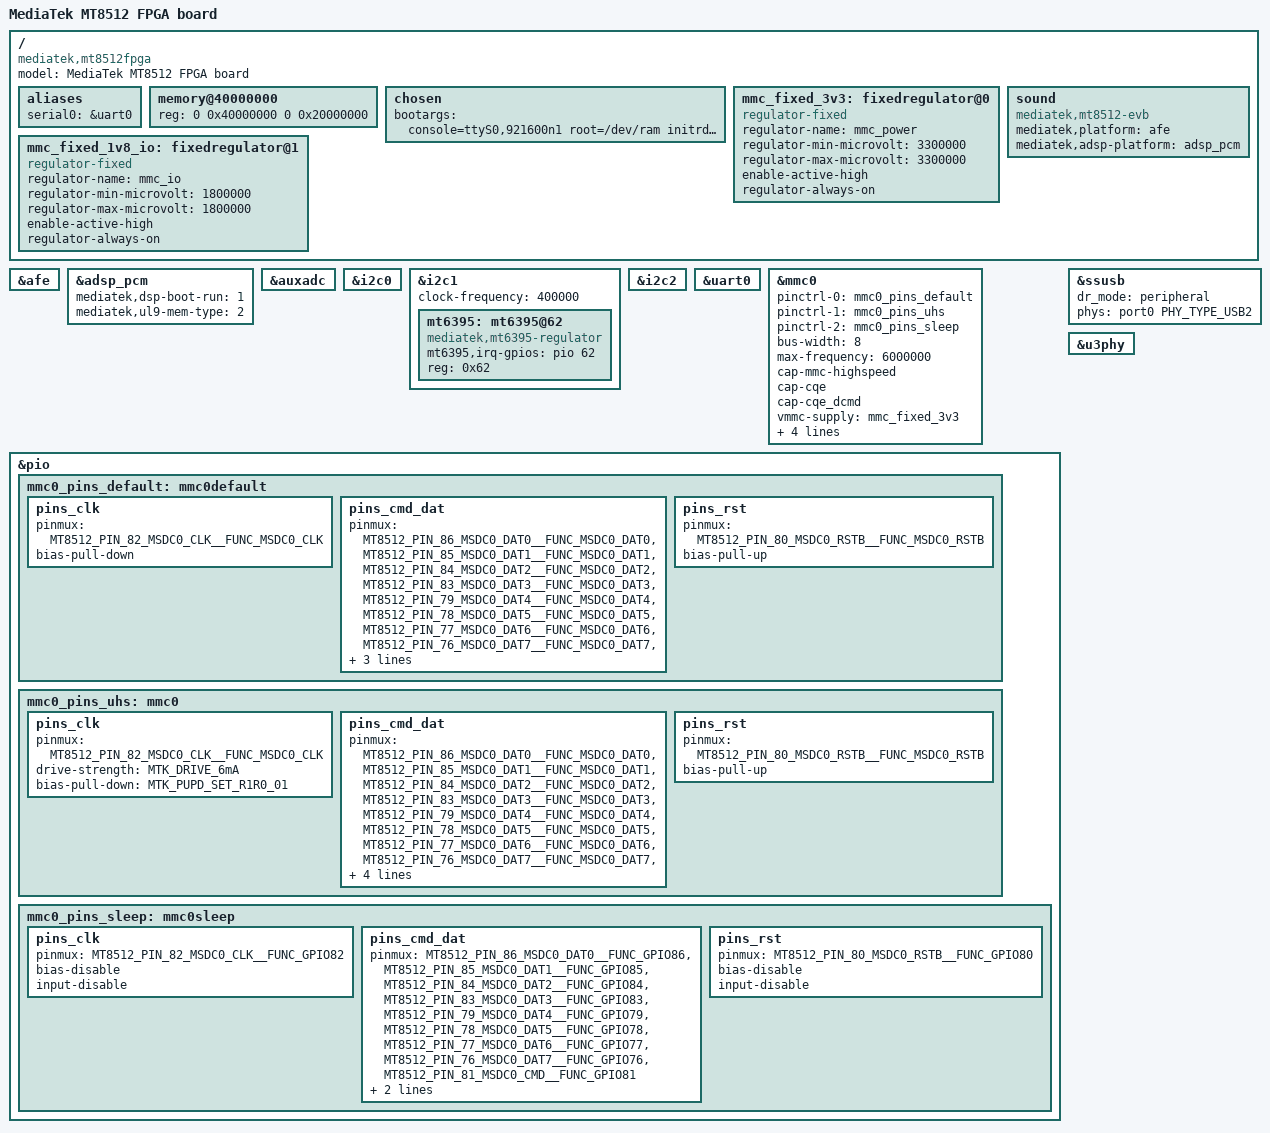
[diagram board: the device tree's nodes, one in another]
/*
 * Copyright (c) 2019 MediaTek Inc.
 *
 * SPDX-License-Identifier: (GPL-2.0 OR MIT)
 */

/dts-v1/;
#include "mt8512fpga.dtsi"

/ {
	model = "MediaTek MT8512 FPGA board";
	compatible = "mediatek,mt8512fpga", "mediatek,mt8512";

	aliases {
		serial0 = &uart0;
	};

	memory@40000000 {
		device_type = "memory";
		reg = <0 0x40000000 0 0x20000000>;
	};

	chosen {
		bootargs = "console=ttyS0,921600n1 root=/dev/ram \
		initrd=0x51000000,0x91EA22 earlycon=uart8250,mmio32,0x11002000 \
		initcall_debug loglevel=8 androidboot.hardware=mt8512 \
		firmware_class.path=/vendor/firmware";
	};

	mmc_fixed_3v3: fixedregulator@0 {
		compatible = "regulator-fixed";
		regulator-name = "mmc_power";
		regulator-min-microvolt = <3300000>;
		regulator-max-microvolt = <3300000>;
		enable-active-high;
		regulator-always-on;
	};

	mmc_fixed_1v8_io: fixedregulator@1 {
		compatible = "regulator-fixed";
		regulator-name = "mmc_io";
		regulator-min-microvolt = <1800000>;
		regulator-max-microvolt = <1800000>;
		enable-active-high;
		regulator-always-on;
	};

	sound: sound {
		compatible = "mediatek,mt8512-evb";
		mediatek,platform = <&afe>;
		mediatek,adsp-platform = <&adsp_pcm>;
		status = "okay";
	};
};

&afe {
	status = "okay";
};

&adsp_pcm {
	mediatek,dsp-boot-run = <1>;
	mediatek,ul9-mem-type = <2>;
	status = "okay";
};

&auxadc {
	status = "okay";
};

&i2c0 {
	status = "okay";
};

&i2c1 {
	status = "okay";
	clock-frequency = <400000>;

	mt6395: mt6395@62 {
		compatible = "mediatek,mt6395-regulator";
		mt6395,irq-gpios = <&pio 62 0x0>;
		reg = <0x62>;
		status = "okay";
	};
};

&i2c2 {
	status = "okay";
};

&uart0 {
	status = "okay";
};

&mmc0 {
	status = "okay";
	pinctrl-names = "default", "state_uhs", "sleep";
	pinctrl-0 = <&mmc0_pins_default>;
	pinctrl-1 = <&mmc0_pins_uhs>;
	pinctrl-2 = <&mmc0_pins_sleep>;
	bus-width = <8>;
	max-frequency = <6000000>;
	cap-mmc-highspeed;
	cap-cqe;
	cap-cqe_dcmd;
	vmmc-supply = <&mmc_fixed_3v3>;
	vqmmc-supply = <&mmc_fixed_1v8_io>;
	non-removable;
	no-sd;
	no-sdio;
};

&pio {
	pinctrl-names = "default";

	mmc0_pins_default: mmc0default {
		pins_clk {
			pinmux = <MT8512_PIN_82_MSDC0_CLK__FUNC_MSDC0_CLK>;
			bias-pull-down;
		};

		pins_cmd_dat {
			pinmux = <MT8512_PIN_86_MSDC0_DAT0__FUNC_MSDC0_DAT0>,
				 <MT8512_PIN_85_MSDC0_DAT1__FUNC_MSDC0_DAT1>,
				 <MT8512_PIN_84_MSDC0_DAT2__FUNC_MSDC0_DAT2>,
				 <MT8512_PIN_83_MSDC0_DAT3__FUNC_MSDC0_DAT3>,
				 <MT8512_PIN_79_MSDC0_DAT4__FUNC_MSDC0_DAT4>,
				 <MT8512_PIN_78_MSDC0_DAT5__FUNC_MSDC0_DAT5>,
				 <MT8512_PIN_77_MSDC0_DAT6__FUNC_MSDC0_DAT6>,
				 <MT8512_PIN_76_MSDC0_DAT7__FUNC_MSDC0_DAT7>,
				 <MT8512_PIN_81_MSDC0_CMD__FUNC_MSDC0_CMD>;
			input-enable;
			bias-pull-up;
		};

		pins_rst {
			pinmux = <MT8512_PIN_80_MSDC0_RSTB__FUNC_MSDC0_RSTB>;
			bias-pull-up;
		};
	};

	mmc0_pins_uhs: mmc0 {
		pins_clk {
			pinmux = <MT8512_PIN_82_MSDC0_CLK__FUNC_MSDC0_CLK>;
			drive-strength = <MTK_DRIVE_6mA>;
			bias-pull-down = <MTK_PUPD_SET_R1R0_01>;
		};

		pins_cmd_dat {
			pinmux = <MT8512_PIN_86_MSDC0_DAT0__FUNC_MSDC0_DAT0>,
				 <MT8512_PIN_85_MSDC0_DAT1__FUNC_MSDC0_DAT1>,
				 <MT8512_PIN_84_MSDC0_DAT2__FUNC_MSDC0_DAT2>,
				 <MT8512_PIN_83_MSDC0_DAT3__FUNC_MSDC0_DAT3>,
				 <MT8512_PIN_79_MSDC0_DAT4__FUNC_MSDC0_DAT4>,
				 <MT8512_PIN_78_MSDC0_DAT5__FUNC_MSDC0_DAT5>,
				 <MT8512_PIN_77_MSDC0_DAT6__FUNC_MSDC0_DAT6>,
				 <MT8512_PIN_76_MSDC0_DAT7__FUNC_MSDC0_DAT7>,
				 <MT8512_PIN_81_MSDC0_CMD__FUNC_MSDC0_CMD>;
			input-enable;
			drive-strength = <MTK_DRIVE_6mA>;
			bias-pull-up = <MTK_PUPD_SET_R1R0_01>;
		};

		pins_rst {
			pinmux = <MT8512_PIN_80_MSDC0_RSTB__FUNC_MSDC0_RSTB>;
			bias-pull-up;
		};
	};

	mmc0_pins_sleep: mmc0sleep {
		pins_clk {
			pinmux = <MT8512_PIN_82_MSDC0_CLK__FUNC_GPIO82>;
			bias-disable;
			input-disable;
		};

		pins_cmd_dat {
			pinmux = <MT8512_PIN_86_MSDC0_DAT0__FUNC_GPIO86>,
				 <MT8512_PIN_85_MSDC0_DAT1__FUNC_GPIO85>,
				 <MT8512_PIN_84_MSDC0_DAT2__FUNC_GPIO84>,
				 <MT8512_PIN_83_MSDC0_DAT3__FUNC_GPIO83>,
				 <MT8512_PIN_79_MSDC0_DAT4__FUNC_GPIO79>,
				 <MT8512_PIN_78_MSDC0_DAT5__FUNC_GPIO78>,
				 <MT8512_PIN_77_MSDC0_DAT6__FUNC_GPIO77>,
				 <MT8512_PIN_76_MSDC0_DAT7__FUNC_GPIO76>,
				 <MT8512_PIN_81_MSDC0_CMD__FUNC_GPIO81>;
			bias-disable;
			input-disable;
		};

		pins_rst {
			pinmux = <MT8512_PIN_80_MSDC0_RSTB__FUNC_GPIO80>;
			bias-disable;
			input-disable;
		};
	};
};

&ssusb {
	dr_mode = "peripheral";
	phys = <&port0 PHY_TYPE_USB2>;
	status="okay";
};

&u3phy {
	status = "okay";
};
